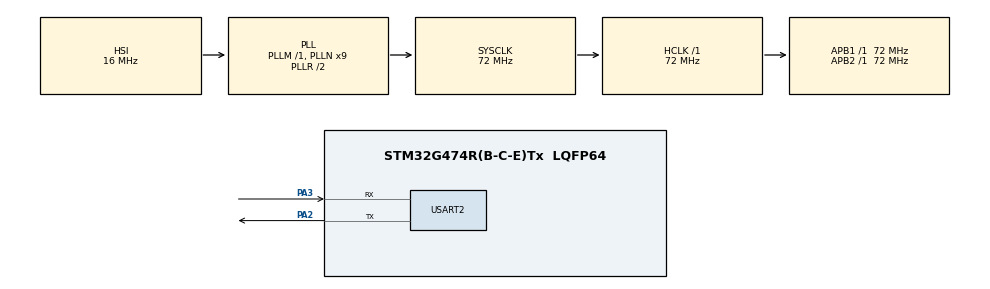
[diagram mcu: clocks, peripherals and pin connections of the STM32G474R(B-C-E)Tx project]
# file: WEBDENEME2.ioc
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Dma.Request0=USART2_TX
Dma.USART2_TX.0.Direction=DMA_MEMORY_TO_PERIPH
Dma.USART2_TX.0.EventEnable=DISABLE
Dma.USART2_TX.0.Instance=DMA1_Channel1
Dma.USART2_TX.0.MemDataAlignment=DMA_MDATAALIGN_BYTE
Dma.USART2_TX.0.MemInc=DMA_MINC_ENABLE
Dma.USART2_TX.0.Mode=DMA_CIRCULAR
Dma.USART2_TX.0.PeriphDataAlignment=DMA_PDATAALIGN_BYTE
Dma.USART2_TX.0.PeriphInc=DMA_PINC_DISABLE
Dma.USART2_TX.0.Polarity=HAL_DMAMUX_REQ_GEN_RISING
Dma.USART2_TX.0.Priority=DMA_PRIORITY_LOW
Dma.USART2_TX.0.RequestNumber=1
Dma.USART2_TX.0.SignalID=NONE
Dma.USART2_TX.0.SyncEnable=DISABLE
Dma.USART2_TX.0.SyncPolarity=HAL_DMAMUX_SYNC_NO_EVENT
Dma.USART2_TX.0.SyncRequestNumber=1
Dma.USART2_TX.0.SyncSignalID=NONE
Mcu.Family=STM32G4
Mcu.Name=STM32G474R(B-C-E)Tx
Mcu.Package=LQFP64
NVIC.DMA1_Channel1_IRQn=true\:0\:0\:false\:false\:true\:false\:true\:true
NVIC.PriorityGroup=NVIC_PRIORITYGROUP_4
NVIC.USART2_IRQn=true\:0\:0\:false\:false\:true\:true\:true\:true
PA2.Mode=Asynchronous
PA2.Signal=USART2_TX
PA3.Mode=Asynchronous
PA3.Signal=USART2_RX
ProjectManager.HeapSize=0x200
ProjectManager.StackSize=0x400
ProjectManager.TargetToolchain=STM32CubeIDE
RCC.ADC12Freq_Value=72000000
RCC.ADC345Freq_Value=72000000
RCC.AHBFreq_Value=72000000
RCC.APB1Freq_Value=72000000
RCC.APB1TimFreq_Value=72000000
RCC.APB2Freq_Value=72000000
RCC.APB2TimFreq_Value=72000000
RCC.CortexFreq_Value=72000000
RCC.EXTERNAL_CLOCK_VALUE=12288000
RCC.HCLKFreq_Value=72000000
RCC.HSE_VALUE=8000000
RCC.HSI48_VALUE=48000000
RCC.HSI_VALUE=16000000
RCC.LSE_VALUE=32768
RCC.PLLN=9
RCC.SYSCLKFreq_VALUE=72000000
RCC.SYSCLKSource=RCC_SYSCLKSOURCE_PLLCLK
RCC.USBFreq_Value=72000000
RCC.VCOOutputFreq_Value=144000000
USART2.VirtualMode-Asynchronous=VM_ASYNC
VP_SYS_VS_DBSignals.Mode=DisableDeadBatterySignals
board=custom

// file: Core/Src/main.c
/* USER CODE BEGIN Header */
/**
  ******************************************************************************
  * @file           : main.c
  * @brief          : Main program body
  ******************************************************************************
  * @attention
  *
  * Copyright (c) 2025 STMicroelectronics.
  * All rights reserved.
  *
  * This software is licensed under terms that can be found in the LICENSE file
  * in the root directory of this software component.
  * If no LICENSE file comes with this software, it is provided AS-IS.
  *
  ******************************************************************************
  */
/* USER CODE END Header */
#include "main.h"

/* USER CODE BEGIN Includes */
#include <math.h>
#include <stdlib.h>
/* USER CODE END Includes */

/* USER CODE BEGIN PD */
#define BUFFER_SIZE 100
/* USER CODE END PD */

UART_HandleTypeDef huart2;
DMA_HandleTypeDef hdma_usart2_tx;

/* USER CODE BEGIN PV */
uint8_t data_buffer[BUFFER_SIZE];
volatile uint32_t sample_counter = 0;
volatile uint8_t transmission_complete = 1;
/* USER CODE END PV */

void SystemClock_Config(void);
static void MX_GPIO_Init(void);
static void MX_DMA_Init(void);
static void MX_USART2_UART_Init(void);
/* USER CODE BEGIN PFP */
void GenerateRealtimeData(void);
/* USER CODE END PFP */

/* USER CODE BEGIN 0 */

void GenerateRealtimeData(void)
{
  for (int i = 0; i < BUFFER_SIZE; i++)
  {
    // Dinamik sine wave + noise oluştur
    double angle = (2.0 * M_PI * (sample_counter + i)) / (BUFFER_SIZE * 2);
    double sine_val = sin(angle);

    // Biraz gürültü ekle
    double noise = ((rand() % 21) - 10) / 100.0; // -0.1 to +0.1

    // Değeri 0-255 aralığına çevir
    sine_val = (sine_val + noise + 1.0) * 127.5;

    // Sınırları kontrol et
    if (sine_val < 0) sine_val = 0;
    if (sine_val > 255) sine_val = 255;

    data_buffer[i] = (uint8_t)sine_val;
  }

  sample_counter += BUFFER_SIZE;
}

// DMA transmission complete callback
void HAL_UART_TxCpltCallback(UART_HandleTypeDef *huart)
{
  if (huart->Instance == USART2)
  {
    transmission_complete = 1;
  }
}

/* USER CODE END 0 */

int main(void)
{

  /* MCU Configuration--------------------------------------------------------*/

  /* Reset of all peripherals, Initializes the Flash interface and the Systick. */
  HAL_Init();

  /* Configure the system clock */
  SystemClock_Config();

  /* Initialize all configured peripherals */
  MX_GPIO_Init();
  MX_DMA_Init();
  MX_USART2_UART_Init();

  /* USER CODE BEGIN 2 */

  // Random seed başlat
  srand(HAL_GetTick());

  // İlk veri paketini hazırla ve gönder
  GenerateRealtimeData();
  HAL_UART_Transmit_DMA(&huart2, data_buffer, BUFFER_SIZE);
  transmission_complete = 0;

  /* USER CODE END 2 */

  /* Infinite loop */
  while (1)
  {

    /* USER CODE BEGIN 3 */
    // DMA tamamlandığında yeni veri gönder
    if (transmission_complete)
    {
      HAL_Delay(100); // 10ms bekle
      transmission_complete = 0;
      GenerateRealtimeData();
      HAL_UART_Transmit_DMA(&huart2, data_buffer, BUFFER_SIZE);
    }

    HAL_Delay(1); // CPU'yu rahatlatmak için
  }
  /* USER CODE END 3 */
}

void SystemClock_Config(void)
{
  RCC_OscInitTypeDef RCC_OscInitStruct = {0};
  RCC_ClkInitTypeDef RCC_ClkInitStruct = {0};

  /** Configure the main internal regulator output voltage
  */
  HAL_PWREx_ControlVoltageScaling(PWR_REGULATOR_VOLTAGE_SCALE1);

  /** Initializes the RCC Oscillators according to the specified parameters
  * in the RCC_OscInitTypeDef structure.
  */
  RCC_OscInitStruct.OscillatorType = RCC_OSCILLATORTYPE_HSI;
  RCC_OscInitStruct.HSIState = RCC_HSI_ON;
  RCC_OscInitStruct.HSICalibrationValue = RCC_HSICALIBRATION_DEFAULT;
  RCC_OscInitStruct.PLL.PLLState = RCC_PLL_ON;
  RCC_OscInitStruct.PLL.PLLSource = RCC_PLLSOURCE_HSI;
  RCC_OscInitStruct.PLL.PLLM = RCC_PLLM_DIV1;
  RCC_OscInitStruct.PLL.PLLN = 9;
  RCC_OscInitStruct.PLL.PLLP = RCC_PLLP_DIV2;
  RCC_OscInitStruct.PLL.PLLQ = RCC_PLLQ_DIV2;
  RCC_OscInitStruct.PLL.PLLR = RCC_PLLR_DIV2;
  if (HAL_RCC_OscConfig(&RCC_OscInitStruct) != HAL_OK)
  {
    Error_Handler();
  }

  /** Initializes the CPU, AHB and APB buses clocks
  */
  RCC_ClkInitStruct.ClockType = RCC_CLOCKTYPE_HCLK|RCC_CLOCKTYPE_SYSCLK
                              |RCC_CLOCKTYPE_PCLK1|RCC_CLOCKTYPE_PCLK2;
  RCC_ClkInitStruct.SYSCLKSource = RCC_SYSCLKSOURCE_PLLCLK;
  RCC_ClkInitStruct.AHBCLKDivider = RCC_SYSCLK_DIV1;
  RCC_ClkInitStruct.APB1CLKDivider = RCC_HCLK_DIV1;
  RCC_ClkInitStruct.APB2CLKDivider = RCC_HCLK_DIV1;

  if (HAL_RCC_ClockConfig(&RCC_ClkInitStruct, FLASH_LATENCY_2) != HAL_OK)
  {
    Error_Handler();
  }
}

static void MX_USART2_UART_Init(void)
{

  huart2.Instance = USART2;
  huart2.Init.BaudRate = 115200;
  huart2.Init.WordLength = UART_WORDLENGTH_8B;
  huart2.Init.StopBits = UART_STOPBITS_1;
  huart2.Init.Parity = UART_PARITY_NONE;
  huart2.Init.Mode = UART_MODE_TX;
  huart2.Init.HwFlowCtl = UART_HWCONTROL_NONE;
  huart2.Init.OverSampling = UART_OVERSAMPLING_16;
  huart2.Init.OneBitSampling = UART_ONE_BIT_SAMPLE_DISABLE;
  huart2.Init.ClockPrescaler = UART_PRESCALER_DIV1;
  huart2.AdvancedInit.AdvFeatureInit = UART_ADVFEATURE_NO_INIT;
  if (HAL_UART_Init(&huart2) != HAL_OK)
  {
    Error_Handler();
  }
  if (HAL_UARTEx_SetTxFifoThreshold(&huart2, UART_TXFIFO_THRESHOLD_1_8) != HAL_OK)
  {
    Error_Handler();
  }
  if (HAL_UARTEx_DisableFifoMode(&huart2) != HAL_OK)
  {
    Error_Handler();
  }

}

static void MX_DMA_Init(void)
{

  /* DMA controller clock enable */
  __HAL_RCC_DMAMUX1_CLK_ENABLE();
  __HAL_RCC_DMA1_CLK_ENABLE();

  /* DMA interrupt init */
  /* DMA1_Channel1_IRQn interrupt configuration */
  HAL_NVIC_SetPriority(DMA1_Channel1_IRQn, 0, 0);
  HAL_NVIC_EnableIRQ(DMA1_Channel1_IRQn);

}

static void MX_GPIO_Init(void)
{

  /* GPIO Ports Clock Enable */
  __HAL_RCC_GPIOA_CLK_ENABLE();

}

void Error_Handler(void)
{
  __disable_irq();
  while (1)
  {
  }
}
